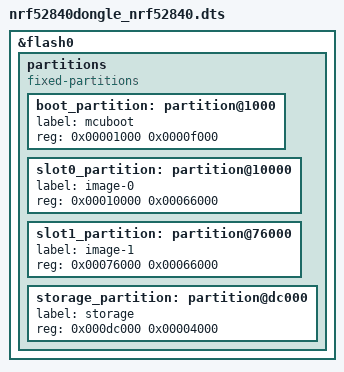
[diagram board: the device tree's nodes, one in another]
/*
 * Copyright (c) 2018-2023 Nordic Semiconductor ASA
 * Copyright (c) 2017 Linaro Limited
 *
 * SPDX-License-Identifier: Apache-2.0
 */

/dts-v1/;
#include "nrf52840dongle_nrf52840_common.dtsi"

/* Flash partition table compatible with the onboard USB bootloader */

&flash0 {
	partitions {
		compatible = "fixed-partitions";
		#address-cells = <1>;
		#size-cells = <1>;

		/* MCUboot placed after Nordic MBR.
		 * The size of this partition ensures that MCUBoot can
		 * be built with CDC ACM support and w/o optimizations.
		 */
		boot_partition: partition@1000 {
			label = "mcuboot";
			reg = <0x00001000 0x0000f000>;
		};

		slot0_partition: partition@10000 {
			label = "image-0";
			reg = <0x00010000 0x00066000>;
		};

		slot1_partition: partition@76000 {
			label = "image-1";
			reg = <0x00076000 0x00066000>;
		};

		storage_partition: partition@dc000 {
			label = "storage";
			reg = <0x000dc000 0x00004000>;
		};

		/* Onboard USB bootloader <0xe0000 0x1c000>
		 *
		 * In addition, the last and second last flash pages
		 * are used by the onboard USB bootloader and MBR to store
		 * settings.
		 */
	};
};
